# LPC800 register map
File version: 0.2
CPU: CM0 r0p0, little endian, no MPU, no FPU, 2 interrupt priority bits
Registers are 32-bit, read-write, reset 0x0 unless marked. A register's access mark holds for its fields unless they carry their own. Offsets are from the block's base; [hi:lo] are bit positions; {n}, {i} and the like mark numbered series.

## I2C — I2C-bus interface
Base 0x40050000
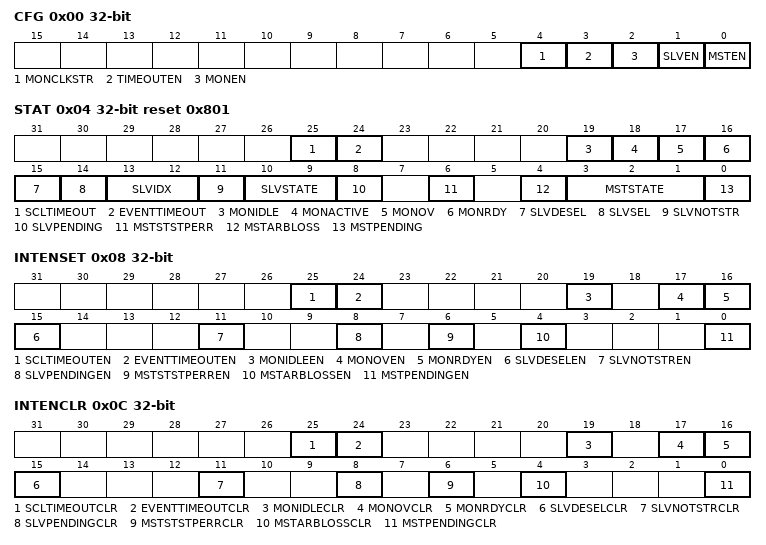
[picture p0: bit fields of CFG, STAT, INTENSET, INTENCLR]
0x00 CFG — Configuration for shared functions.
  [4] MONCLKSTR — Monitor function Clock Stretching.
    0=DISABLED_THE_MONITO (Disabled. The monitor function will not perform clock stretching. Software may not always be able to read data provided by the monitor function before it is overwritten. This mode may be used when non-invasive monitoring is critical.); 1=ENABLED_THE_MONITOR (Enabled. The monitor function will perform clock stretching in order to ensure that software can read all incoming data supplied by the monitor function.)
  [3] TIMEOUTEN — I2C bus Time-out Enable. When disabled, timeout flags will be automatically cleared.
    0=DISABLED_TIME_OUT_F (Disabled. Time-out function is disabled.); 1=ENABLED_TIME_OUT_FU (Enabled. Time-out function is enabled. Both types of time-out flags will be generated and will cause interrupts if they are enabled. Typically, only one timeout will be used in a system.)
  [2] MONEN — Monitor Enable. When disabled, configurations settings for the Monitor function are not changed, but the Monitor function is internally reset.
    0=DISABLED_THE_I2C_MO (Disabled. The I2C monitor function is disabled.); 1=ENABLED_THE_I2C_MON (Enabled. The I2C monitor function is enabled.)
  [1] SLVEN — Slave Enable. When disabled, configurations settings for the Slave function are not changed, but the Slave function is internally reset.
    0=DISABLED_THE_I2C_SL (Disabled. The I2C slave function is disabled.); 1=ENABLED_THE_I2C_SLA (Enabled. The I2C slave function is enabled.)
  [0] MSTEN — Master Enable. When disabled, configurations settings for the Master function are not changed, but the Master function is internally reset.
    0=DISABLED_THE_I2C_MA (Disabled. The I2C Master function is disabled.); 1=ENABLED_THE_I2C_MAS (Enabled. The I2C Master function is enabled.)
0x04 STAT reset 0x801 — Status register for Master, Slave, and Monitor functions.
  [25] SCLTIMEOUT — SCL Time-out Interrupt flag. Indicates when SCL has remained low longer than the time specific by the TIMEOUT register. The flag is cleared by writing a 1 to this bit.
    0=NO_TIME_OUT_SCL_LOW (No time-out. SCL low time has not caused a timeout.); 1=TIME_OUT_SCL_LOW_TI (Time-out. SCL low time has caused a timeout.)
  [24] EVENTTIMEOUT — Event Time-out Interrupt flag. Indicates when the time between events has been longer than the time specified by the TIMEOUT register. Events include Start, Stop, and clock edges. The case of SCL remaining low longer than TIMEOUT is not reported by this flag, it is reported in by the SCL Time-out flag. The flag is cleared by writing a 1 to this bit.
    0=NO_TIME_OUT_I2C_BUS (No time-out. I2C bus events have not caused a timeout.); 1=EVENT_TIME_OUT_THE_ (Event time-out. The time between I2C bus events has been longer than the time specified by the I2C Timeout register.)
  [19] MONIDLE — Monitor Idle flag. This flag is set when the Monitor function sees the I2C bus change from active to inactive. This can be used by software to decide when to process data accumulated by the Monitor function. This flag will cause an interrupt when set if enabled via the INTENSET register . The flag can be cleared by writing a 1 to this bit.
    0=NOT_IDLE_THE_I2C_BU (Not idle. The I2C bus is not idle, or this flag has been cleared by software.); 1=IDLE_THE_I2C_BUS_HA (Idle. The I2C bus has gone idle at least once since the last time this flag was cleared by software.)
  [18] MONACTIVE — Monitor Active flag. This flag indicates when the Monitor function considers the I2C bus to be active. Active is defined here as when some Master is on the bus: a bus Start has occurred more recently than a bus Stop.
    0=INACTIVE_THE_MONITO (Inactive. The Monitor function considers the I2C bus to be inactive.); 1=ACTIVE_THE_MONITOR_ (Active. The Monitor function considers the I2C bus to be active.)
  [17] MONOV — Monitor Overflow flag.
    0=NO_OVERRUN_MONITOR_ (No overrun. Monitor data has not overrun.); 1=OVERRUN_A_MONITOR_D (Overrun. A Monitor data overrun has occurred. This can only happen when Monitor clock stretching not enabled via the MONCLKSTR bit in the CFG register. Writing 1 to this bit clears the flag.)
  [16] MONRDY — Monitor Ready. This flag is cleared when the MONRXDAT register is read.
    0=NO_DATA_THE_MONITOR (No data. The Monitor function does not currently have data available.); 1=DATA_WAITING_THE_MO (Data waiting. The Monitor function has data waiting to be read.)
  [15] SLVDESEL — Slave Deselected flag. This flag will cause an interrupt when set if enabled via INTENSET. This flag can be cleared by writing a 1 to this bit.
    0=NOT_DESELECTED_THE_ (Not deselected. The Slave function has not become deselected. This does not mean that it is currently selected. That information can be found in the SLVSEL flag.); 1=DESELECTED_THE_SLAV (Deselected. The Slave function has become deselected. This is specifically caused by the SLVSEL flag changing from 1 to 0. See the description of SLVSEL for details on when that event occurs.)
  [14] SLVSEL — Slave selected flag. SLVSEL is set after an address match when software tells the Slave function to acknowledge the address. It is cleared when another address cycle presents an address that does not match an enabled address on the Slave function, when slave software decides to Nack a matched address, or when there is a Stop detected on the bus. SLVSEL is not cleared if software Nacks data.
    0=NOT_SELECTED_THE_SL (Not selected. The Slave function is not currently selected.); 1=SELECTED_THE_SLAVE_ (Selected. The Slave function is currently selected.)
  [13:12] SLVIDX — Slave address match Index. This field is valid when the I2C slave function has been selected by receiving an address that matches one of the slave addresses defined by any enabled slave address registers, and provides an identification of the address that was matched. It is possible that more than one address could be matched, but only one match can be reported here.
    {v}=SLAVE_ADDRESS_{v}_WAS_ (Slave address {v} was matched.) (v=0..3)
  [11] SLVNOTSTR — Slave Not Stretching. Indicates when the slave function is stretching the I2C clock. This is needed in order to gracefully invoke Deep Sleep or Power-down modes during slave operation. This read-only flag reflects the slave function status in real time.
    0=STRETCHING_THE_SLAV (Stretching. The slave function is currently stretching the I2C bus clock. Deep-Sleep or Power-down mode cannot be entered at this time.); 1=NOT_STRETCHING_THE_ (Not stretching. The slave function is not currently stretching the I 2C bus clock. Deep-sleep or Power-down mode could be entered at this time.)
  [10:9] SLVSTATE — Slave State code. Each value of this field indicates a specific required service for the Slave function. All other values are reserved.
    0=RECEIVED_ADDRESS_PL (Received. Address plus R/W received. At least one of the four slave addresses has been matched by hardware.); 1=DATA_AVAILABLE_RECE (Data available. Received data is available (Slave Receiver mode).); 2=DATA_READY_FOR_TRANS (Data ready for transmit. Data can be transmitted (Slave Transmitter mode).)
  [8] SLVPENDING — Slave Pending. Indicates whether the Slave function needs software service. This flag will cause an interrupt when set if enabled via INTENSET. The SLVPENDING flag is read-only and is automatically cleared when a 1 is written to the SLVCONTINUE bit in the MSTCTL register.
    0=NO_SERVICE_NEEDED_T (No service needed. The Slave function does not currently need service.); 1=SERVICE_NEEDED_THE_ (Service needed. The Slave function needs service. Information on what is needed can be found in the adjacent SLVSTATE field.)
  [6] MSTSTSTPERR — Master Start/Stop Error flag. This flag can be cleared by software writing a 1 to this bit. It is also cleared automatically a 1 is written to MstContinue.
    0=NO_STARTSTOP_ERROR_ (No Start/Stop Error has occurred.); 1=STARTSTOP_ERROR_HAS (Start/stop error has occurred. The Master function has experienced a Start/Stop Error. A Start or Stop was detected at a time when it is not allowed by the I2C specification. The Master interface has stopped driving the bus and gone to an idle state, no action is required. A request for a Start could be made, or software could attempt to insure that the bus has not stalled.)
  [4] MSTARBLOSS — Master Arbitration Loss flag. This flag can be cleared by software writing a 1 to this bit. It is also cleared automatically a 1 is written to MSTCONTINUE.
    0=NO_LOSS_NO_ARBITRAT (No loss. No Arbitration Loss has occurred.); 1=ARBITRATION_LOSS_TH (Arbitration loss. The Master function has experienced an Arbitration Loss. At this point, the Master function has already stopped driving the bus and gone to an idle state. Software can respond by doing nothing, or by sending a Start in order to attempt to gain control of the bus when it next becomes idle.)
  [3:1] MSTSTATE — Master State code. Each value of this field indicates a specific required service for the Master function. All other values are reserved.
    0=IDLE_THE_MASTER_FUN (Idle. The Master function is available to be used for a new transaction.); 1=RECEIVE_READY_RECEI (Receive ready. Received data available (Master Receiver mode). Address plus Read was previously sent and Acknowledged by slave.); 2=TRANSMIT_READY_DATA (Transmit ready. Data can be transmitted (Master Transmitter mode). Address plus Write was previously sent and Acknowledged by slave.); 3=ADDRESS_SLAVE_NACKE (Address. Slave Nacked address.); 4=DATA_SLAVE_NACKED_T (Data. Slave Nacked transmitted data.)
  [0] MSTPENDING — Master Pending. Indicates whether the Master function needs software service. This flag will cause an interrupt when set if enabled via the INTENSET register. The MSTPENDING flag is automatically cleared when a 1 is written to the MSTCONTINUE bit in the MSTCTL register.
    0=NO_SERVICE_NEEDED_T (No service needed. The Master function does not currently need service.); 1=SERVICE_NEEDED_THE_ (Service needed. The Master function needs service. Information on what is needed can be found in the adjacent MSTSTATE field.)
0x08 INTENSET — Interrupt Enable Set and read register.
  [25] SCLTIMEOUTEN — SCL Timeout interrupt Enable.
    0=THE_SCL_TIMEOUT_INTE0 (The SCL Timeout interrupt is disabled.); 1=THE_SCL_TIMEOUT_INTE1 (The SCL Timeout interrupt is enabled.)
  [24] EVENTTIMEOUTEN — Event Timeout interrupt Enable.
    0=THE_EVENT_TIMEOUT_IN0 (The Event Timeout interrupt is disabled.); 1=THE_EVENT_TIMEOUT_IN1 (The Event Timeout interrupt is enabled.)
  [19] MONIDLEEN — Monitor Idle interrupt Enable.
    0=THE_MONIDLE_INTERRUP0 (The MonIdle interrupt is disabled.); 1=THE_MONIDLE_INTERRUP1 (The MonIdle interrupt is enabled.)
  [17] MONOVEN — Monitor Overrun interrupt Enable.
    0=THE_MONOV_INTERRUPT_0 (The MonOv interrupt is disabled.); 1=THE_MONOV_INTERRUPT_1 (The MonOv interrupt is enabled.)
  [16] MONRDYEN — Monitor data Ready interrupt Enable.
    0=THE_MONRDY_INTERRUPT0 (The MonRdy interrupt is disabled.); 1=THE_MONRDY_INTERRUPT1 (The MonRdy interrupt is enabled.)
  [15] SLVDESELEN — Slave Deselect interrupt Enable.
    0=THE_SLVDESEL_INTERRU0 (The SlvDeSel interrupt is disabled.); 1=THE_SLVDESEL_INTERRU1 (The SlvDeSel interrupt is enabled.)
  [11] SLVNOTSTREN — Slave Not Stretching interrupt Enable.
    0=THE_SLVNOTSTR_INTERR0 (The SlvNotStr interrupt is disabled.); 1=THE_SLVNOTSTR_INTERR1 (The SlvNotStr interrupt is enabled.)
  [8] SLVPENDINGEN — Slave Pending interrupt Enable.
    0=THE_SLVPENDING_INTER0 (The SlvPending interrupt is disabled.); 1=THE_SLVPENDING_INTER1 (The SlvPending interrupt is enabled.)
  [6] MSTSTSTPERREN — Master Start/Stop Error interrupt Enable.
    0=THE_MSTSTSTPERR_INTE0 (The MstStStpErr interrupt is disabled.); 1=THE_MSTSTSTPERR_INTE1 (The MstStStpErr interrupt is enabled.)
  [4] MSTARBLOSSEN — Master Arbitration Loss interrupt Enable.
    0=THE_MSTARBLOSS_INTER0 (The MstArbLoss interrupt is disabled.); 1=THE_MSTARBLOSS_INTER1 (The MstArbLoss interrupt is enabled.)
  [0] MSTPENDINGEN — Master Pending interrupt Enable.
    0=THE_MSTPENDING_INTER0 (The MstPending interrupt is disabled.); 1=THE_MSTPENDING_INTER1 (The MstPending interrupt is enabled.)
0x0C INTENCLR wo reset not defined — Interrupt Enable Clear register.
  [25] SCLTIMEOUTCLR — SCL Timeout interrupt clear.
  [24] EVENTTIMEOUTCLR — Event Timeout interrupt clear.
  [19] MONIDLECLR — Monitor Idle interrupt clear.
  [17] MONOVCLR — Monitor Overrun interrupt clear.
  [16] MONRDYCLR — Monitor data Ready interrupt clear.
  [15] SLVDESELCLR — Slave Deselect interrupt clear.
  [11] SLVNOTSTRCLR — Slave Not Stretching interrupt clear.
  [8] SLVPENDINGCLR — Slave Pending interrupt clear.
  [6] MSTSTSTPERRCLR — Master Start/Stop Error interrupt clear.
  [4] MSTARBLOSSCLR — Master Arbitration Loss interrupt clear.
  [0] MSTPENDINGCLR — Master Pending interrupt clear. Writing 1 to this bit clears the corresponding bit in the INTENSET register if implemented.
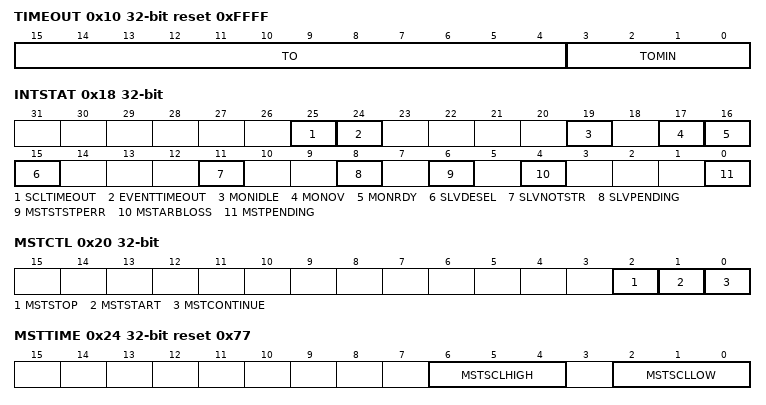
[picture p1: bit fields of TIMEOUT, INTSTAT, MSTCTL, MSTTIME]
0x10 TIMEOUT reset 0xFFFF — Time-out value register.
  [15:4] TO — Timeout time value. Specifies the timeout interval value in increments of 16 I2C function clocks, as defined by the CLKDIV register. To change this value while I2C is in operation, disable all time-outs, write a new value to TIMEOUT, then re-enable time-outs. 0x000 = A time-out will occur after 16 counts of the I2C function clock. 0x001 = A time-out will occur after 32 counts of the I2C function clock. ... 0xFFF = A timeout will occur after 65,536 counts of the I2C function clock.
  [3:0] TOMIN — Timeout time value, bottom four bits. These are hard-wired to 0xF. This gives a minimum timeout of 16 I2C function clocks and also a timeout resolution of 16 I2C function clocks.
0x14 DIV — Clock pre-divider for the entire I2C block. This determines what time increments are used for the MSTTIME and SLVTIME registers.
  [15:0] DIVVAL — This field controls how the clock (PCLK) is used by the I2C functions that need an internal clock in order to operate. 0x0000 = PCLK is used directly by the I2C function. 0x0001 = PCLK is divided by 2 before use by the I 2C function. 0x0002 = PCLK is divided by 3 before use by the I 2C function. ... 0xFFFF = PCLK is divided by 65,536 before use by the I2C function.
0x18 INTSTAT ro — Interrupt Status register for Master, Slave, and Monitor functions.
  [25] SCLTIMEOUT — SCL Timeout Interrupt flag.
  [24] EVENTTIMEOUT — Event Timeout Interrupt flag.
  [19] MONIDLE — Monitor Idle flag.
  [17] MONOV — Monitor Overflow flag.
  [16] MONRDY — Monitor Ready.
  [15] SLVDESEL — Slave Deselected flag.
  [11] SLVNOTSTR — Slave Not Stretching status.
  [8] SLVPENDING — Slave Pending.
  [6] MSTSTSTPERR — Master Start/Stop Error flag.
  [4] MSTARBLOSS — Master Arbitration Loss flag.
  [0] MSTPENDING — Master Pending.
0x20 MSTCTL — Master control register.
  [2] MSTSTOP — Master Stop control. This bit is write-only.
    0=NO_EFFECT_; 1=STOP_A_STOP_WILL_BE (Stop. A Stop will be generated on the I2C bus at the next allowed time, preceded by a Nack to the slave if the master is receiving data from the slave (Master Receiver mode).)
  [1] MSTSTART — Master Start control. This bit is write-only.
    0=NO_EFFECT_; 1=START_A_START_WILL_ (Start. A Start will be generated on the I2C bus at the next allowed time.)
  [0] MSTCONTINUE — Master Continue. This bit is write-only.
    0=NO_EFFECT_; 1=CONTINUE_INFORMS_TH (Continue. Informs the Master function to continue to the next operation. This must done after writing transmit data, reading received data, or any other housekeeping related to the next bus operation.)
0x24 MSTTIME reset 0x77 — Master timing configuration.
  [6:4] MSTSCLHIGH — Master SCL High time. Specifies the minimum high time that will be asserted by this master on SCL. Other masters in a multi-master system could shorten this time. This corresponds to the parameter tHIGH in the I2C bus specification. I2C bus specification parameters tSU;STO and tHD;STA have the same values and are also controlled by MSTSCLHIGH.
    0=2_CLOCKS_MINIMUM_SC (2 clocks. Minimum SCL high time is 2 clock of the I2C clock pre-divider.); 1=3_CLOCKS_MINIMUM_SC (3 clocks. Minimum SCL high time is 3 clocks of the I2C clock pre-divider .); {v}={v+2}_CLOCKS_MINIMUM_SC ({v+2} clocks. Minimum SCL high time is {v+2} clock of the I2C clock pre-divider.) (v=2..6); 7=9_CLOCKS_MINIMUM_SC (9 clocks. Minimum SCL high time is 9 clocks of the I2C clock pre-divider.)
  [2:0] MSTSCLLOW — Master SCL Low time. Specifies the minimum low time that will be asserted by this master on SCL. Other devices on the bus (masters or slaves) could lengthen this time. This corresponds to the parameter t LOW in the I2C bus specification. I2C bus specification parameters tBUF and tSU;STA have the same values and are also controlled by MSTSCLLOW.
    {v}={v+2}_CLOCKS_MINIMUM_SC ({v+2} clocks. Minimum SCL low time is {v+2} clocks of the I2C clock pre-divider.) (v=0..7)
0x28 MSTDAT reset not defined read-modifies — Combined Master receiver and transmitter data register.
  [7:0] DATA — Master function data register. Read: read the most recently received data for the Master function. Write: transmit data using the Master function.
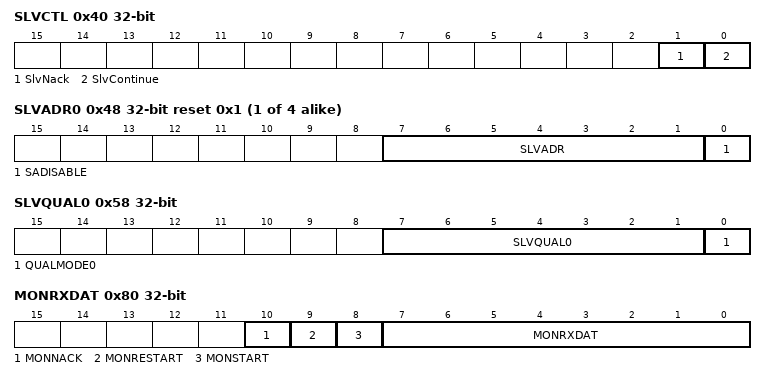
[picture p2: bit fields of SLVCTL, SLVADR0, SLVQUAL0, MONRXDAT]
0x40 SLVCTL — Slave control register.
  [1] SlvNack — Slave Nack.
    0=NO_EFFECT_; 1=NACK_CAUSES_THE_SLA (Nack. Causes the Slave function to Nack the master when the slave is receiving data from the master (Slave Receiver mode).)
  [0] SlvContinue — Slave Continue.
    0=NO_EFFECT_; 1=CONTINUE_INFORMS_TH (Continue. Informs the Slave function to continue to the next operation. This must done after writing transmit data, reading received data, or any other housekeeping related to the next bus operation.)
0x44 SLVDAT reset not defined read-modifies — Combined Slave receiver and transmitter data register.
  [7:0] DATA — Slave function data register. Read: read the most recently received data for the Slave function. Write: transmit data using the Slave function.
{0x48+4i} SLVADR{i} (i=0..3) reset 0x1 — Slave address 0.
  [7:1] SLVADR — Seven bit slave address that is compared to received addresses if enabled.
  [0] SADISABLE — Slave Address n Disable.
    0=ENABLED_SLAVE_ADDRE (Enabled. Slave Address n is enabled and will be recognized with any changes specified by the SLVQUAL0 register.); 1=IGNORED_SLAVE_ADDRES (Ignored Slave Address n is ignored.)
0x58 SLVQUAL0 — Slave Qualification for address 0.
  [7:1] SLVQUAL0 — Slave address Qualifier for address 0. A value of 0 causes the address in SLVADR0 to be used as-is, assuming that it is enabled. If QUALMODE0 = 0, any bit in this field which is set to 1 will cause an automatic match of the corresponding bit of the received address when it is compared to the SLVADR0 register. If QUALMODE0 = 1, an address range is matched for address 0. This range extends from the value defined by SLVADR0 to the address defined by SLVQUAL0 (address matches when SLVADR0[7:1] less or equal than received address less or equal than SLVQUAL0[7:1]).
  [0] QUALMODE0 — Reserved. Read value is undefined, only zero should be written.
    0=THE_SLVQUAL0_FIELD_I0 (The SLVQUAL0 field is used as a logical mask for matching address 0.); 1=THE_SLVQUAL0_FIELD_I1 (The SLVQUAL0 field is used to extend address 0 matching in a range of addresses.)
0x80 MONRXDAT ro — Monitor receiver data register.
  [10] MONNACK — Monitor Received Nack.
    0=ACKNOWLEDGED_THE_DA (Acknowledged. The data currently being provided by the monitor function was acknowledged by at least one master or slave receiver.); 1=NOT_ACKNOWLEDGED_TH (Not acknowledged. The data currently being provided by the monitor function was not acknowledged by any receiver.)
  [9] MONRESTART — Monitor Received Repeated Start.
    0=NO_START_DETECT_THE (No start detect. The monitor function has not detected a Repeated Start event on the I2C bus.); 1=REPEATED_START_DETEC (Repeated start detect. The monitor function has detected a Repeated Start event on the I 2C bus.)
  [8] MONSTART — Monitor Received Start.
    0=NO_DETECT_THE_MONIT (No detect. The monitor function has not detected a Start event on the I2C bus.); 1=START_DETECT_THE_MO (Start detect. The monitor function has detected a Start event on the I2C bus.)
  [7:0] MONRXDAT — Monitor function Receiver Data. This reflects every data byte that passes on the I2C pins, and adds indication of Start, Repeated Start, and data Nack.
